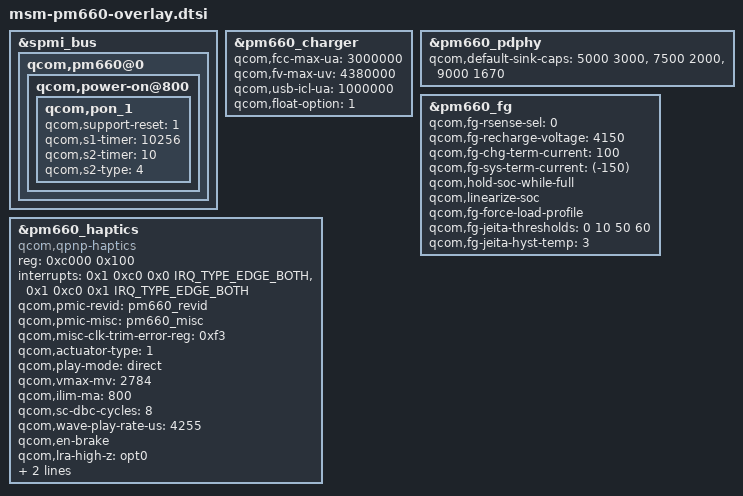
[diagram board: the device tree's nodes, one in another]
/* SPDX-License-Identifier: GPL-2.0 */

&spmi_bus {
	qcom,pm660@0 {
		qcom,power-on@800 {
			qcom,pon_1 {
				qcom,support-reset = <1>;
				qcom,s1-timer = <10256>;
				qcom,s2-timer = <10>;
				qcom,s2-type = <4>;
			};
		};
	};
};

&pm660_charger {
	qcom,fcc-max-ua = <3000000>;
	qcom,fv-max-uv = <4380000>;
	qcom,usb-icl-ua = <1000000>;
	qcom,float-option = <1>;
};

&pm660_pdphy {
	qcom,default-sink-caps = <5000 3000>, /* 5V @ 3A */
				 <7500 2000>, /* 7.5V @ 2A */
				 <9000 1670>; /* 9V @ 1.67A */
};

&pm660_fg {
	qcom,fg-rsense-sel = <0>;
	qcom,fg-recharge-voltage = <4150>;  //WeiYu ++ for HW recharge
	qcom,fg-chg-term-current = <100>;
	qcom,fg-sys-term-current = <(-150)>;
	qcom,hold-soc-while-full;
	qcom,linearize-soc; //ASUS_BSP
	qcom,fg-force-load-profile;
	qcom,fg-jeita-thresholds = <0 10 50 60>;
	qcom,fg-jeita-hyst-temp = <3>;
};

&pm660_haptics {
        // leds-qpnp-vibrator  
	/*
	status = "okay";
	compatible = "qcom,qpnp-vibrator";
	reg = <0xc000 0x100>;
	label = "vibrator";
	qcom,vib-timeout-ms = <15000>;
	qcom,vib-vtg-level-mV = <3100>;
	qcom,mode = "manual"; */
	
	// led-qpnp-haptics
	compatible = "qcom,qpnp-haptics";
	reg = <0xc000 0x100>;
	interrupts = <0x1 0xc0 0x0 IRQ_TYPE_EDGE_BOTH>,
			<0x1 0xc0 0x1 IRQ_TYPE_EDGE_BOTH>;
	interrupt-names = "hap-sc-irq", "hap-play-irq";
	qcom,pmic-revid = <&pm660_revid>;
	qcom,pmic-misc = <&pm660_misc>;
	qcom,misc-clk-trim-error-reg = <0xf3>;
	qcom,actuator-type = <1>;
	qcom,play-mode = "direct";
	qcom,vmax-mv = <2784>;
	qcom,ilim-ma = <800>;
	qcom,sc-dbc-cycles = <8>;
	qcom,wave-play-rate-us = <4255>;
	qcom,en-brake;
	qcom,lra-high-z = "opt0";
	qcom,lra-auto-res-mode = "qwd";
	qcom,lra-res-cal-period = <4>;
};
